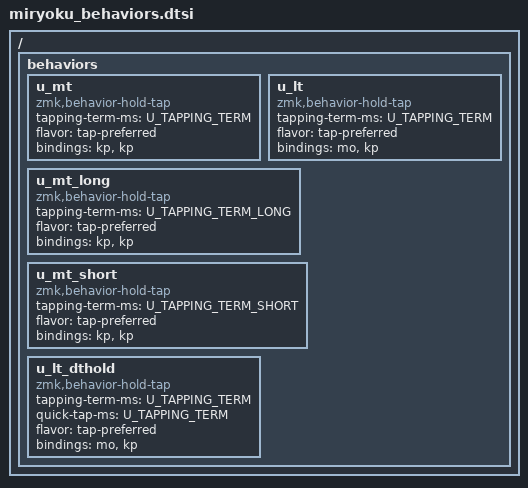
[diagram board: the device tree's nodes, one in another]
// Copyright 2022 Manna Harbour
// https://github.com/manna-harbour/miryoku

/ {
  behaviors {
    u_mt: u_mt {
      compatible = "zmk,behavior-hold-tap";
      #binding-cells = <2>;
      tapping-term-ms = <U_TAPPING_TERM>;
      flavor = "tap-preferred";
      bindings = <&kp>, <&kp>;
    };
    u_lt: u_lt {
      compatible = "zmk,behavior-hold-tap";
      #binding-cells = <2>;
      tapping-term-ms = <U_TAPPING_TERM>;
      flavor = "tap-preferred";
      bindings = <&mo>, <&kp>;
    };
    u_mt_long: u_mt_long {
      compatible = "zmk,behavior-hold-tap";
      #binding-cells = <2>;
      tapping-term-ms = <U_TAPPING_TERM_LONG>;
      flavor = "tap-preferred";
      bindings = <&kp>, <&kp>;
    };
    u_mt_short: u_mt_short {
      compatible = "zmk,behavior-hold-tap";
      #binding-cells = <2>;
      tapping-term-ms = <U_TAPPING_TERM_SHORT>;
      flavor = "tap-preferred";
      bindings = <&kp>, <&kp>;
    };
    u_lt_dthold: u_lt_dthold {
      compatible = "zmk,behavior-hold-tap";
      #binding-cells = <2>;
      tapping-term-ms = <U_TAPPING_TERM>;
      quick-tap-ms = <U_TAPPING_TERM>;
      flavor = "tap-preferred";
      bindings = <&mo>, <&kp>;
    };
  };
};
